VERSION "Chassis_CAN_v1.0"

NS_ :

BS_:

BU_: SIL_TEST_CTRL CHASSIS_GW ACCEL_CTRL BRAKE_CTRL STEERING_CTRL ADAS_WARN_CTRL Vector__XXX VEHICLE_BASE_TEST_CTRL EMS_POLICE_TX EMS_AMB_TX EMS_ALERT_RX

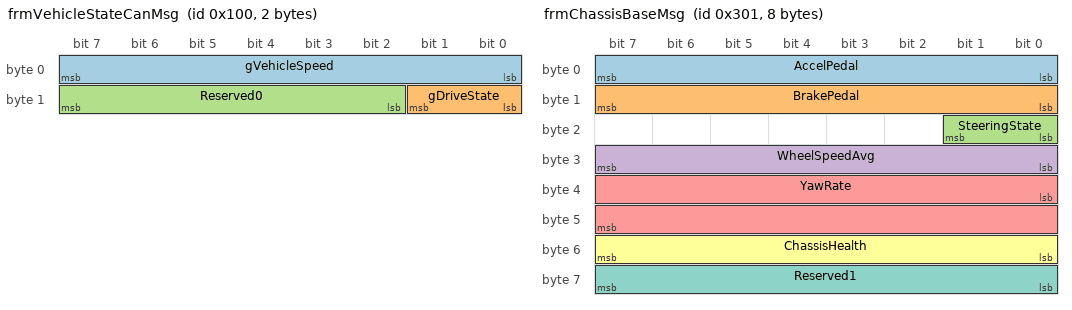
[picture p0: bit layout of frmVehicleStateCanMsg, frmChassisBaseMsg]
BO_ 256 frmVehicleStateCanMsg: 2 SIL_TEST_CTRL
 SG_ gVehicleSpeed : 0|8@1+ (1,0) [0|255] "km/h" CHASSIS_GW,ADAS_WARN_CTRL
 SG_ gDriveState   : 8|2@1+ (1,0) [0|3]   ""     CHASSIS_GW,ADAS_WARN_CTRL
 SG_ Reserved0     : 10|6@1+ (1,0) [0|0]  ""     Vector__XXX

BO_ 257 frmSteeringCanMsg: 1 SIL_TEST_CTRL
 SG_ SteeringInput : 0|1@1+ (1,0) [0|1] "" CHASSIS_GW,STEERING_CTRL
 SG_ Reserved0     : 1|7@1+ (1,0) [0|0] "" Vector__XXX

BO_ 769 frmChassisBaseMsg: 8 CHASSIS_GW
 SG_ AccelPedal      : 0|8@1+ (1,0) [0|100] "%" ACCEL_CTRL,ADAS_WARN_CTRL
 SG_ BrakePedal      : 8|8@1+ (1,0) [0|100] "%" BRAKE_CTRL,ADAS_WARN_CTRL
 SG_ SteeringState   : 16|2@1+ (1,0) [0|3]  "" STEERING_CTRL,ADAS_WARN_CTRL
 SG_ WheelSpeedAvg   : 24|8@1+ (1,0) [0|255] "km/h" ADAS_WARN_CTRL
 SG_ YawRate         : 32|16@1+ (1,0) [0|65535] "deg/s" ADAS_WARN_CTRL
 SG_ ChassisHealth   : 48|8@1+ (1,0) [0|255] "" ADAS_WARN_CTRL
 SG_ Reserved1       : 56|8@1+ (1,0) [0|0] "" Vector__XXX

BO_ 258 frmPedalInputCanMsg: 2 SIL_TEST_CTRL
 SG_ AccelPedal       : 0|8@1+ (1,0) [0|100] "%" ACCEL_CTRL
 SG_ BrakePedal       : 8|8@1+ (1,0) [0|100] "%" BRAKE_CTRL

BO_ 259 frmSteeringStateCanMsg: 1 CHASSIS_GW
 SG_ SteeringState    : 0|2@1+ (1,0) [0|3] "" STEERING_CTRL
 SG_ Reserved0        : 2|6@1+ (1,0) [0|0] "" Vector__XXX

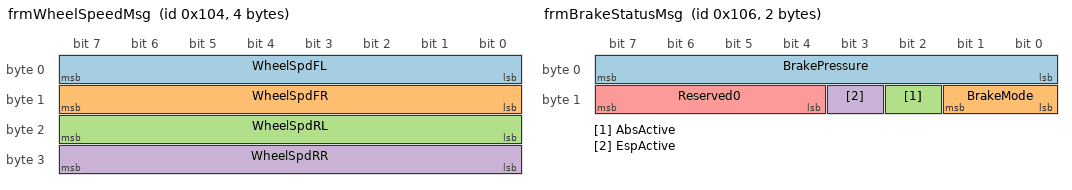
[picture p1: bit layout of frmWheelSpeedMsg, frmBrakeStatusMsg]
BO_ 260 frmWheelSpeedMsg: 4 CHASSIS_GW
 SG_ WheelSpdFL       : 0|8@1+ (1,0) [0|255] "km/h" ACCEL_CTRL,BRAKE_CTRL,STEERING_CTRL
 SG_ WheelSpdFR       : 8|8@1+ (1,0) [0|255] "km/h" ACCEL_CTRL,BRAKE_CTRL,STEERING_CTRL
 SG_ WheelSpdRL       : 16|8@1+ (1,0) [0|255] "km/h" ACCEL_CTRL,BRAKE_CTRL,STEERING_CTRL
 SG_ WheelSpdRR       : 24|8@1+ (1,0) [0|255] "km/h" ACCEL_CTRL,BRAKE_CTRL,STEERING_CTRL

BO_ 261 frmYawAccelMsg: 4 CHASSIS_GW
 SG_ YawRate          : 0|16@1+ (1,0) [0|65535] "deg/s" BRAKE_CTRL,STEERING_CTRL
 SG_ LatAccel         : 16|16@1+ (1,0) [0|65535] "0.01m/s2" BRAKE_CTRL,STEERING_CTRL

BO_ 262 frmBrakeStatusMsg: 2 BRAKE_CTRL
 SG_ BrakePressure    : 0|8@1+ (1,0) [0|255] "%" CHASSIS_GW
 SG_ BrakeMode        : 8|2@1+ (1,0) [0|3] "" CHASSIS_GW
 SG_ AbsActive        : 10|1@1+ (1,0) [0|1] "" CHASSIS_GW
 SG_ EspActive        : 11|1@1+ (1,0) [0|1] "" CHASSIS_GW
 SG_ Reserved0        : 12|4@1+ (1,0) [0|0] "" Vector__XXX

BO_ 263 frmAccelStatusMsg: 2 ACCEL_CTRL
 SG_ AccelRequest     : 0|8@1+ (1,0) [0|100] "%" CHASSIS_GW
 SG_ TorqueRequest    : 8|8@1+ (1,0) [0|255] "Nm" CHASSIS_GW

BO_ 264 frmSteeringTorqueMsg: 2 STEERING_CTRL
 SG_ SteeringTorque   : 0|12@1+ (1,0) [0|4095] "0.1Nm" CHASSIS_GW
 SG_ SteeringAssistLv : 12|4@1+ (1,0) [0|15] "" CHASSIS_GW

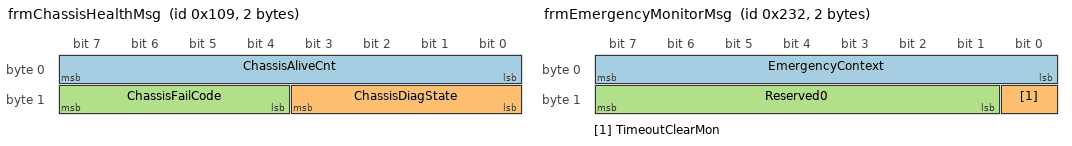
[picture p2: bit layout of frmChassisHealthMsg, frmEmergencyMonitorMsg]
BO_ 265 frmChassisHealthMsg: 2 CHASSIS_GW
 SG_ ChassisAliveCnt  : 0|8@1+ (1,0) [0|255] "" SIL_TEST_CTRL
 SG_ ChassisDiagState : 8|4@1+ (1,0) [0|15] "" SIL_TEST_CTRL
 SG_ ChassisFailCode  : 12|4@1+ (1,0) [0|15] "" SIL_TEST_CTRL

BO_ 562 frmEmergencyMonitorMsg: 2 EMS_ALERT_RX
 SG_ EmergencyContext : 0|8@1+ (1,0) [0|255] "" SIL_TEST_CTRL,CHASSIS_GW
 SG_ TimeoutClearMon  : 8|1@1+ (1,0) [0|1] "" SIL_TEST_CTRL,CHASSIS_GW
 SG_ Reserved0        : 9|7@1+ (1,0) [0|0] "" Vector__XXX

CM_ BO_ 256 "Flow_001 core vehicle state input.";
CM_ BO_ 257 "Flow_002 steering input.";
CM_ BO_ 769 "Comm_102 baseline chassis aggregate message (Req_103~Req_105).";

CM_ BO_ 258 "Chassis baseline: acceleration pedal and brake pedal input.";
CM_ BO_ 259 "Chassis baseline: steering state produced from normalized steering input.";
CM_ BO_ 260 "Chassis baseline: per-wheel speed distribution.";
CM_ BO_ 261 "Chassis baseline: yaw rate and lateral acceleration.";
CM_ BO_ 262 "Chassis baseline: brake pressure and ESC/ABS status.";
CM_ BO_ 263 "Chassis baseline: acceleration request and torque request.";
CM_ BO_ 264 "Chassis baseline: steering torque and assist level.";
CM_ BO_ 265 "Chassis health/diagnostic state.";
CM_ BO_ 562 "Emergency context monitor shadow frame for SIL CAN tracing.";

BA_DEF_ BO_ "GenMsgCycleTime" INT 0 10000;
BA_DEF_DEF_ "GenMsgCycleTime" 0;
BA_ "GenMsgCycleTime" BO_ 256 100;
BA_ "GenMsgCycleTime" BO_ 257 100;
BA_ "GenMsgCycleTime" BO_ 769 100;

BA_ "GenMsgCycleTime" BO_ 258 100;
BA_ "GenMsgCycleTime" BO_ 259 100;
BA_ "GenMsgCycleTime" BO_ 260 100;
BA_ "GenMsgCycleTime" BO_ 261 100;
BA_ "GenMsgCycleTime" BO_ 262 100;
BA_ "GenMsgCycleTime" BO_ 263 100;
BA_ "GenMsgCycleTime" BO_ 264 100;
BA_ "GenMsgCycleTime" BO_ 265 100;
BA_ "GenMsgCycleTime" BO_ 562 100;

  0 "P"
  1 "R"
  2 "N"
  3 "D" ;

  0 "NoInput"
  1 "Input" ;

  0 "Stable"
  1 "LeftTurn"
  2 "RightTurn"
  3 "Fault" ;

  0 "Normal"
  1 "Assist"
  2 "Emergency"
  3 "Fault" ;

  0 "Inactive"
  1 "Active" ;

  0 "Inactive"
  1 "Active" ;

  0 "NoClear"
  1 "Clear" ;
